AUTOSAR XML (schema 4-0-3)
package /ComponentTypes
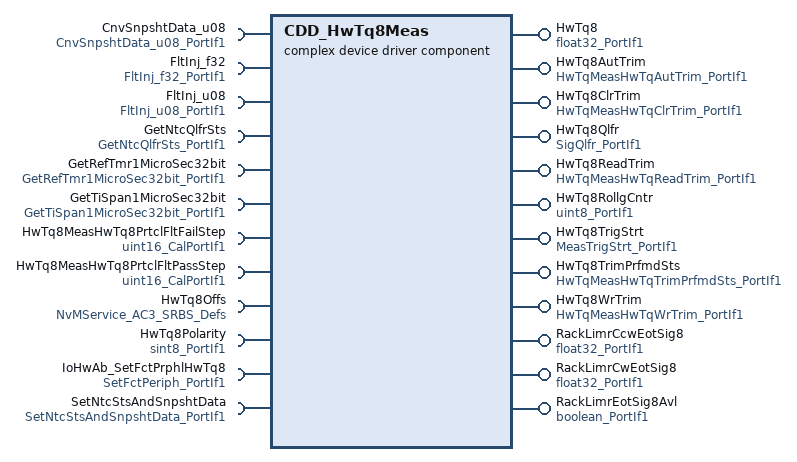
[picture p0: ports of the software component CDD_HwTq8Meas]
  complex device driver sw component type CDD_HwTq8Meas
    12 x provide port:
      HwTq8: nonqueued-sender-com-spec{data-element=Val, init-value=0}, provided-interface=float32_PortIf1
      HwTq8AutTrim: server-com-spec{operation=Oper, queue-length=1}, provided-interface=HwTqMeasHwTqAutTrim_PortIf1
      HwTq8ClrTrim: server-com-spec{operation=Oper, queue-length=1}, provided-interface=HwTqMeasHwTqClrTrim_PortIf1
      HwTq8Qlfr: nonqueued-sender-com-spec{data-element=Val, init-value=0}, provided-interface=SigQlfr_PortIf1
      HwTq8ReadTrim: server-com-spec{operation=Oper, queue-length=1}, provided-interface=HwTqMeasHwTqReadTrim_PortIf1
      HwTq8RollgCntr: nonqueued-sender-com-spec{data-element=Val, init-value=0}, provided-interface=uint8_PortIf1
      HwTq8TrigStrt: server-com-spec{operation=Oper, queue-length=1}, provided-interface=MeasTrigStrt_PortIf1
      HwTq8TrimPrfmdSts: server-com-spec{operation=Oper, queue-length=1}, provided-interface=HwTqMeasHwTqTrimPrfmdSts_PortIf1
      HwTq8WrTrim: server-com-spec{operation=Oper, queue-length=1}, provided-interface=HwTqMeasHwTqWrTrim_PortIf1
      RackLimrCcwEotSig8: nonqueued-sender-com-spec{data-element=Val, init-value=0}, provided-interface=float32_PortIf1
      RackLimrCwEotSig8: nonqueued-sender-com-spec{data-element=Val, init-value=0}, provided-interface=float32_PortIf1
      RackLimrEotSig8Avl: nonqueued-sender-com-spec{data-element=Logl, init-value=0}, provided-interface=boolean_PortIf1
    12 x require port:
      CnvSnpshtData_u08: client-com-spec=Oper, required-interface=CnvSnpshtData_u08_PortIf1
      FltInj_f32: client-com-spec=Oper, required-interface=FltInj_f32_PortIf1
      FltInj_u08: client-com-spec=Oper, required-interface=FltInj_u08_PortIf1
      GetNtcQlfrSts: client-com-spec=Oper, required-interface=GetNtcQlfrSts_PortIf1
      GetRefTmr1MicroSec32bit: client-com-spec=Oper, required-interface=GetRefTmr1MicroSec32bit_PortIf1
      GetTiSpan1MicroSec32bit: client-com-spec=Oper, required-interface=GetTiSpan1MicroSec32bit_PortIf1
      HwTq8MeasHwTq8PrtclFltFailStep: parameter-require-com-spec{init-value=2521, parameter=Val}, required-interface=uint16_CalPortIf1
      HwTq8MeasHwTq8PrtclFltPassStep: parameter-require-com-spec{init-value=1000, parameter=Val}, required-interface=uint16_CalPortIf1
      HwTq8Offs: required-com-specs=[EraseBlock, GetErrorStatus, InvalidateNvBlock, ReadBlock, RestoreBlockDefaults, SetRamBlockStatus, WriteBlock], required-interface=NvMService_AC3_SRBS_Defs
      HwTq8Polarity: nonqueued-receiver-com-spec{data-element=Val, filter=data-filter-type=ALWAYS, init-value=1}, required-interface=sint8_PortIf1
      IoHwAb_SetFctPrphlHwTq8: client-com-spec=Oper, required-interface=SetFctPeriph_PortIf1
      SetNtcStsAndSnpshtData: client-com-spec=Oper, required-interface=SetNtcStsAndSnpshtData_PortIf1
    behavior CDD_HwTq8Meas_InternalBehavior
      ar-typed-per-instance-memorys:
        15 x data, all with sw-calibration-access=READ-ONLY:
          HwTq8ComStsErrCntr: type=uint8
          HwTq8IntSnsrErrCntr: type=uint8
          HwTq8MsgMissRxCnt: type=uint32
          HwTq8Offs: type=HwTqOffsRec1
          HwTq8PrevHwTq8: type=float32
          HwTq8PrevRollgCntr: type=uint8
          RackLimrCcwEot8: type=float32
          RackLimrCwEot8: type=float32
          RackLimrEot8Avl: type=boolean
          RackLimrEot8Data{0..2}: type=uint8
          RackLimrEot8Id{2..4}DataReadCmpl: type=boolean
      operation invoked event OIT_HwTq0MeasHwTq0AutTrim_Oper_HwTq0MeasHwTq0AutTrim_Oper: start-on-event=HwTq8AutTrim_Oper, operation=HwTq8AutTrim.Oper
      operation invoked event OIT_HwTq0MeasHwTq0ClrTrim_Oper_HwTq0MeasHwTq0ClrTrim_Oper: start-on-event=HwTq8ClrTrim_Oper, operation=HwTq8ClrTrim.Oper
      4 x timing event:
        CDD_HwTq0Meas_InitEvent: start-on-event=HwTq8MeasInit1, period=0
        TMT_HwTq0MeasPer1: start-on-event=HwTq8MeasPer1, period=0.002
        TMT_HwTq0MeasPer3: start-on-event=HwTq8MeasPer2, period=0.1
        TMT_HwTq8MeasPer3Stub: start-on-event=HwTq8MeasPer3Stub, period=0.002
      4 x operation invoked event:
        OIT_HwTq0MeasHwTq0ReadTrim_Oper_HwTq0MeasHwTq0ReadTrim_Oper: start-on-event=HwTq8ReadTrim_Oper, operation=HwTq8ReadTrim.Oper
        OIT_HwTq0MeasTrigStrt_Oper_HwTq0MeasTrgStrt_Oper: start-on-event=HwTq8TrigStrt_Oper, operation=HwTq8TrigStrt.Oper
        OIT_HwTq0MeasHwTq0TrimPrfmdSts_Oper_HwTq0MeasHwTq0TrimPrfmdSts_Oper: start-on-event=HwTq8TrimPrfmdSts_Oper, operation=HwTq8TrimPrfmdSts.Oper
        OIT_HwTq0MeasHwTq0WrTrim_Oper_HwTq0MeasHwTq0WrTrim_Oper: start-on-event=HwTq8WrTrim_Oper, operation=HwTq8WrTrim.Oper
      port-api-options:
        enable-take-address=false, indirect-api=false, port=CnvSnpshtData_u08
        enable-take-address=false, indirect-api=false, port=FltInj_f32
        enable-take-address=false, indirect-api=false, port=FltInj_u08
        enable-take-address=false, indirect-api=false, port=GetNtcQlfrSts
        enable-take-address=false, indirect-api=false, port=GetRefTmr1MicroSec32bit
        enable-take-address=false, indirect-api=false, port=GetTiSpan1MicroSec32bit
        enable-take-address=false, indirect-api=false, port=HwTq8
        enable-take-address=false, indirect-api=false, port=HwTq8AutTrim
        enable-take-address=false, indirect-api=false, port=HwTq8ClrTrim
        enable-take-address=false, indirect-api=false, port=HwTq8MeasHwTq8PrtclFltFailStep
        enable-take-address=false, indirect-api=false, port=HwTq8MeasHwTq8PrtclFltPassStep
        enable-take-address=false, indirect-api=false, port=HwTq8Offs
        enable-take-address=false, indirect-api=false, port=HwTq8Polarity
        enable-take-address=false, indirect-api=false, port=HwTq8Qlfr
        enable-take-address=false, indirect-api=false, port=HwTq8ReadTrim
        enable-take-address=false, indirect-api=false, port=HwTq8RollgCntr
        enable-take-address=false, indirect-api=false, port=HwTq8TrigStrt
        enable-take-address=false, indirect-api=false, port=HwTq8TrimPrfmdSts
        enable-take-address=false, indirect-api=false, port=HwTq8WrTrim
        enable-take-address=false, indirect-api=false, port=IoHwAb_SetFctPrphlHwTq8
        enable-take-address=false, indirect-api=false, port=RackLimrCcwEotSig8
        enable-take-address=false, indirect-api=false, port=RackLimrCwEotSig8
        enable-take-address=false, indirect-api=false, port=RackLimrEotSig8Avl
        enable-take-address=false, indirect-api=false, port=SetNtcStsAndSnpshtData
      10 x runnable:
        HwTq8AutTrim_Oper
          sync call SC_HwTq0Offs_SetRamBlockStatus: operation=HwTq8Offs.SetRamBlockStatus, timeout=0
        HwTq8ClrTrim_Oper
          sync call SC_HwTq0Offs_SetRamBlockStatus: operation=HwTq8Offs.SetRamBlockStatus, timeout=0
        HwTq8MeasInit1
          sync call SC_GetRefTmr1MicroSec32bit_Oper: operation=GetRefTmr1MicroSec32bit.Oper, timeout=0
          sync call SC_GetTiSpan1MicroSec32bit_Oper: operation=GetTiSpan1MicroSec32bit.Oper, timeout=0
          sync call SC_IoHwAb_SetFctPrphlHwTq0_Oper: operation=IoHwAb_SetFctPrphlHwTq8.Oper, timeout=0
        HwTq8MeasPer1
          data-receive-point-by-arguments:
            access REC_HwTq0Polarity_Val: accessed-variable=HwTq8Polarity.Val
          data-send-points:
            6 x access:
              SEND_HwTq0_Val: accessed-variable=HwTq8.Val
              SEND_HwTq0Qlfr_Val: accessed-variable=HwTq8Qlfr.Val
              SEND_HwTq0RollgCntr_Val: accessed-variable=HwTq8RollgCntr.Val
              SEND_RackLimrCcwEotSig0_Val: accessed-variable=RackLimrCcwEotSig8.Val
              SEND_RackLimrCwEotSig0_Val: accessed-variable=RackLimrCwEotSig8.Val
              SEND_RackLimrEotSig0Avl_Logl: accessed-variable=RackLimrEotSig8Avl.Logl
          5 x sync call, all with timeout=0:
            SC_CnvSnpshtData_u08_Oper: operation=CnvSnpshtData_u08.Oper
            SC_FltInj_f32_Oper: operation=FltInj_f32.Oper
            SC_FltInj_u08_Oper: operation=FltInj_u08.Oper
            SC_GetNtcQlfrSts_Oper: operation=GetNtcQlfrSts.Oper
            SC_SetNtcStsAndSnpshtData_Oper: operation=SetNtcStsAndSnpshtData.Oper
        HwTq8MeasPer2
          sync call SC_SetNtcStsAndSnpshtData_Oper: operation=SetNtcStsAndSnpshtData.Oper, timeout=0
        HwTq8MeasPer3Stub
        HwTq8ReadTrim_Oper
        HwTq8TrigStrt_Oper
          sync call SC_GetRefTmr1MicroSec32bit_Oper: operation=GetRefTmr1MicroSec32bit.Oper, timeout=0
          sync call SC_GetTiSpan1MicroSec32bit_Oper: operation=GetTiSpan1MicroSec32bit.Oper, timeout=0
        HwTq8TrimPrfmdSts_Oper
        HwTq8WrTrim_Oper
          sync call SC_HwTq0Offs_SetRamBlockStatus: operation=HwTq8Offs.SetRamBlockStatus, timeout=0
      swc service dependency NvmHwTq8Offs: assigned-datas=[{role=ramBlock, used-data-element=HwTq8Offs}, {role=defaultValue, used-parameter-element=HwTq8OffsDft}], assigned-ports=role-based-port-assignment={port-prototype=HwTq8Offs, role=NvMService_AC3_SRBS_Defs}
        service-needs:
          nv block needs NvmHwTq8Offs: n-data-sets=0, readonly=false, reliability=ERROR-DETECTION, resistant-to-changed-sw=true, restore-at-start=true, store-at-shutdown=true, write-only-once=false, writing-frequency=0, writing-priority=LOW
      shared-parameters:
        parameter data prototype HwTq8OffsDft: sw-calibration-access=READ-WRITE, type=HwTqOffsRec1, init-value=fields=[OffsTrim:0, OffsTrimPrfmdSts:0]
  swc implementation CDD_HwTq8Meas_Implementation: behavior=CDD_HwTq8Meas_InternalBehavior
    code-descriptors:
      code Default: artifact-descriptors=autosar-engineering-object={short-label=Default, category=SWSRC}
